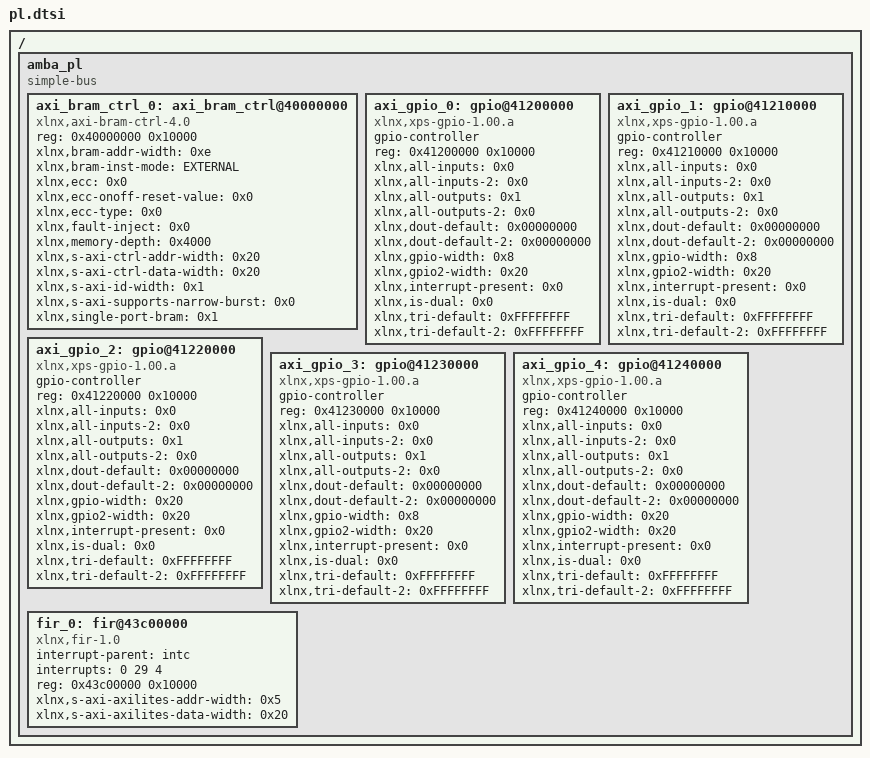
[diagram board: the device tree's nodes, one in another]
/*
 * CAUTION: This file is automatically generated by Xilinx.
 * Version:  
 * Today is: Wed Jun  1 14:24:24 2016
*/


/ {
	amba_pl: amba_pl {
		#address-cells = <1>;
		#size-cells = <1>;
		compatible = "simple-bus";
		ranges ;
		axi_bram_ctrl_0: axi_bram_ctrl@40000000 {
			compatible = "xlnx,axi-bram-ctrl-4.0";
			reg = <0x40000000 0x10000>;
			xlnx,bram-addr-width = <0xe>;
			xlnx,bram-inst-mode = "EXTERNAL";
			xlnx,ecc = <0x0>;
			xlnx,ecc-onoff-reset-value = <0x0>;
			xlnx,ecc-type = <0x0>;
			xlnx,fault-inject = <0x0>;
			xlnx,memory-depth = <0x4000>;
			xlnx,s-axi-ctrl-addr-width = <0x20>;
			xlnx,s-axi-ctrl-data-width = <0x20>;
			xlnx,s-axi-id-width = <0x1>;
			xlnx,s-axi-supports-narrow-burst = <0x0>;
			xlnx,single-port-bram = <0x1>;
		};
		axi_gpio_0: gpio@41200000 {
			#gpio-cells = <2>;
			compatible = "xlnx,xps-gpio-1.00.a";
			gpio-controller ;
			reg = <0x41200000 0x10000>;
			xlnx,all-inputs = <0x0>;
			xlnx,all-inputs-2 = <0x0>;
			xlnx,all-outputs = <0x1>;
			xlnx,all-outputs-2 = <0x0>;
			xlnx,dout-default = <0x00000000>;
			xlnx,dout-default-2 = <0x00000000>;
			xlnx,gpio-width = <0x8>;
			xlnx,gpio2-width = <0x20>;
			xlnx,interrupt-present = <0x0>;
			xlnx,is-dual = <0x0>;
			xlnx,tri-default = <0xFFFFFFFF>;
			xlnx,tri-default-2 = <0xFFFFFFFF>;
		};
		axi_gpio_1: gpio@41210000 {
			#gpio-cells = <2>;
			compatible = "xlnx,xps-gpio-1.00.a";
			gpio-controller ;
			reg = <0x41210000 0x10000>;
			xlnx,all-inputs = <0x0>;
			xlnx,all-inputs-2 = <0x0>;
			xlnx,all-outputs = <0x1>;
			xlnx,all-outputs-2 = <0x0>;
			xlnx,dout-default = <0x00000000>;
			xlnx,dout-default-2 = <0x00000000>;
			xlnx,gpio-width = <0x8>;
			xlnx,gpio2-width = <0x20>;
			xlnx,interrupt-present = <0x0>;
			xlnx,is-dual = <0x0>;
			xlnx,tri-default = <0xFFFFFFFF>;
			xlnx,tri-default-2 = <0xFFFFFFFF>;
		};
		axi_gpio_2: gpio@41220000 {
			#gpio-cells = <2>;
			compatible = "xlnx,xps-gpio-1.00.a";
			gpio-controller ;
			reg = <0x41220000 0x10000>;
			xlnx,all-inputs = <0x0>;
			xlnx,all-inputs-2 = <0x0>;
			xlnx,all-outputs = <0x1>;
			xlnx,all-outputs-2 = <0x0>;
			xlnx,dout-default = <0x00000000>;
			xlnx,dout-default-2 = <0x00000000>;
			xlnx,gpio-width = <0x20>;
			xlnx,gpio2-width = <0x20>;
			xlnx,interrupt-present = <0x0>;
			xlnx,is-dual = <0x0>;
			xlnx,tri-default = <0xFFFFFFFF>;
			xlnx,tri-default-2 = <0xFFFFFFFF>;
		};
		axi_gpio_3: gpio@41230000 {
			#gpio-cells = <2>;
			compatible = "xlnx,xps-gpio-1.00.a";
			gpio-controller ;
			reg = <0x41230000 0x10000>;
			xlnx,all-inputs = <0x0>;
			xlnx,all-inputs-2 = <0x0>;
			xlnx,all-outputs = <0x1>;
			xlnx,all-outputs-2 = <0x0>;
			xlnx,dout-default = <0x00000000>;
			xlnx,dout-default-2 = <0x00000000>;
			xlnx,gpio-width = <0x8>;
			xlnx,gpio2-width = <0x20>;
			xlnx,interrupt-present = <0x0>;
			xlnx,is-dual = <0x0>;
			xlnx,tri-default = <0xFFFFFFFF>;
			xlnx,tri-default-2 = <0xFFFFFFFF>;
		};
		axi_gpio_4: gpio@41240000 {
			#gpio-cells = <2>;
			compatible = "xlnx,xps-gpio-1.00.a";
			gpio-controller ;
			reg = <0x41240000 0x10000>;
			xlnx,all-inputs = <0x0>;
			xlnx,all-inputs-2 = <0x0>;
			xlnx,all-outputs = <0x1>;
			xlnx,all-outputs-2 = <0x0>;
			xlnx,dout-default = <0x00000000>;
			xlnx,dout-default-2 = <0x00000000>;
			xlnx,gpio-width = <0x20>;
			xlnx,gpio2-width = <0x20>;
			xlnx,interrupt-present = <0x0>;
			xlnx,is-dual = <0x0>;
			xlnx,tri-default = <0xFFFFFFFF>;
			xlnx,tri-default-2 = <0xFFFFFFFF>;
		};
		fir_0: fir@43c00000 {
			compatible = "xlnx,fir-1.0";
			interrupt-parent = <&intc>;
			interrupts = <0 29 4>;
			reg = <0x43c00000 0x10000>;
			xlnx,s-axi-axilites-addr-width = <0x5>;
			xlnx,s-axi-axilites-data-width = <0x20>;
		};
	};
};
